# LargeDummyDevice register map
File version: 1.0
Registers are 32-bit, read-write, no defined reset value unless marked. A register's access mark holds for its fields unless they carry their own. Offsets are from the block's base; [hi:lo] are bit positions.

## PERIPHERAL_31
Base 0x4001E000
0x04 REG_1 — Register 1
  [32:31] FIELD_11, [32:30] FIELD_14, [33:29] FIELD_12, [31:28] FIELD_8, [26] FIELD_7, [29:25] FIELD_15, [23:22] FIELD_5, [26:22] FIELD_9, [24:22] FIELD_10, [15] FIELD_3, [15] FIELD_16, [14] FIELD_4, [10:7] FIELD_6, [8:5] FIELD_1, [7:3] FIELD_2, [3:2] FIELD_13
0x08 REG_2 — Register 2
  [33:30] FIELD_8, [30] FIELD_14, [29:25] FIELD_9, [25] FIELD_12, [28:24] FIELD_2, [28:24] FIELD_3, [27:23] FIELD_4, [25:22] FIELD_1, [25:22] FIELD_10, [23:21] FIELD_13, [21:19] FIELD_5, [14:10] FIELD_11, [9:8] FIELD_7, [7] FIELD_16, [11:7] FIELD_17, [3] FIELD_6, [4:0] FIELD_15
0x0C REG_3 — Register 3
  [33:29] FIELD_3, [33:29] FIELD_15, [28] FIELD_11, [29:27] FIELD_18, [23:21] FIELD_9, [24:20] FIELD_4, [20:18] FIELD_7, [19:17] FIELD_8, [20:16] FIELD_1, [14:12] FIELD_2, [11] FIELD_5, [6:5] FIELD_12, [8:5] FIELD_13, [6:4] FIELD_10, [6:3] FIELD_14, [2] FIELD_16, [1:0] FIELD_6, [2:0] FIELD_17
0x10 REG_4 — Register 4
  [31:29] FIELD_19, [30:28] FIELD_12, [27] FIELD_3, [22] FIELD_10, [22] FIELD_11, [21] FIELD_15, [20] FIELD_7, [18] FIELD_13, [18] FIELD_21, [18:15] FIELD_1, [19:15] FIELD_8, [19:15] FIELD_9, [19:15] FIELD_18, [18:15] FIELD_22, [16:13] FIELD_23, [12:11] FIELD_4, [14:10] FIELD_20, [9:7] FIELD_17, [8:6] FIELD_5, [8:6] FIELD_6, [8:5] FIELD_25, [2] FIELD_14, [2] FIELD_16, [5:1] FIELD_2, [2:0] FIELD_24
0x14 REG_5 — Register 5
  [32:30] FIELD_11, [25:24] FIELD_7, [23:20] FIELD_5, [18] FIELD_1, [15] FIELD_2, [19:15] FIELD_8, [17:15] FIELD_10, [14] FIELD_15, [14:13] FIELD_14, [13] FIELD_17, [13:12] FIELD_13, [12:10] FIELD_9, [12:10] FIELD_16, [12:9] FIELD_4, [8:7] FIELD_3, [6:4] FIELD_12, [2:1] FIELD_6
0x18 REG_6 — Register 6
  [34:31] FIELD_13, [33:30] FIELD_16, [31:29] FIELD_8, [31:28] FIELD_21, [25] FIELD_18, [26:24] FIELD_11, [22] FIELD_6, [26:22] FIELD_14, [23:21] FIELD_3, [24:21] FIELD_19, [25:21] FIELD_26, [24:20] FIELD_15, [19] FIELD_24, [16:15] FIELD_12, [14] FIELD_23, [13] FIELD_5, [15:12] FIELD_7, [16:12] FIELD_9, [14:11] FIELD_1, [12:11] FIELD_29, [14:10] FIELD_2, [11:10] FIELD_10, [13:10] FIELD_22, [13:9] FIELD_20, [8] FIELD_17, [10:7] FIELD_27, [9:6] FIELD_28, [5] FIELD_25, [3] FIELD_4
0x1C REG_7 — Register 7
  [17] FIELD_2, [19:16] FIELD_1, [16:15] FIELD_3
0x20 REG_8 — Register 8
  [30:29] FIELD_12, [32:28] FIELD_5, [30:28] FIELD_6, [27:24] FIELD_10, [25:23] FIELD_2, [26:22] FIELD_11, [15] FIELD_9, [15:13] FIELD_4, [12] FIELD_13, [8:6] FIELD_8, [7:3] FIELD_3, [5:1] FIELD_1, [3:0] FIELD_7
0x24 REG_9 — Register 9
  [33:30] FIELD_3, [30] FIELD_15, [29] FIELD_4, [30:27] FIELD_9, [25] FIELD_6, [25:21] FIELD_14, [21:18] FIELD_1, [18] FIELD_11, [22:18] FIELD_19, [18:17] FIELD_2, [20:16] FIELD_18, [15:14] FIELD_10, [16:13] FIELD_12, [17:13] FIELD_17, [13:12] FIELD_7, [10:7] FIELD_13, [9:7] FIELD_21, [9:6] FIELD_5, [3] FIELD_8, [1] FIELD_20, [1:0] FIELD_16
0x28 REG_10 — Register 10
  [33:31] FIELD_15, [32:30] FIELD_9, [33:30] FIELD_18, [26:24] FIELD_14, [26:23] FIELD_7, [25:21] FIELD_3, [22:19] FIELD_11, [15] FIELD_4, [16:14] FIELD_16, [14:11] FIELD_8, [13:11] FIELD_13, [10] FIELD_12, [10] FIELD_17, [11:9] FIELD_19, [7] FIELD_2, [9:7] FIELD_5, [7:4] FIELD_1, [5:2] FIELD_6, [0] FIELD_10
0x2C REG_11 — Register 11
  [34:31] FIELD_2, [34:31] FIELD_8, [31:29] FIELD_1, [31:29] FIELD_10, [28] FIELD_7, [28] FIELD_9, [27:26] FIELD_15, [24] FIELD_17, [21] FIELD_14, [21] FIELD_16, [19:16] FIELD_12, [19:15] FIELD_5, [15:14] FIELD_11, [18:14] FIELD_18, [15:13] FIELD_4, [14:13] FIELD_13, [11:8] FIELD_3, [7:4] FIELD_6
0x30 REG_12 — Register 12
  [31] FIELD_7, [32:31] FIELD_14, [30:28] FIELD_10, [31:28] FIELD_22, [27] FIELD_11, [28:27] FIELD_17, [30:27] FIELD_21, [24] FIELD_3, [22] FIELD_12, [26:22] FIELD_25, [23:21] FIELD_6, [22:18] FIELD_13, [16] FIELD_20, [16] FIELD_26, [15:14] FIELD_4, [15:14] FIELD_9, [17:14] FIELD_15, [16:13] FIELD_23, [15:11] FIELD_5, [15:11] FIELD_24, [14:10] FIELD_19, [9:6] FIELD_18, [8:5] FIELD_16, [7:3] FIELD_1, [4:2] FIELD_2, [5:1] FIELD_8
0x34 REG_13 — Register 13
  [33:31] FIELD_22, [32:30] FIELD_12, [30:28] FIELD_3, [32:28] FIELD_4, [29:27] FIELD_14, [28:27] FIELD_24, [19] FIELD_19, [22:18] FIELD_11, [16:12] FIELD_7, [12] FIELD_18, [13:12] FIELD_21, [15:11] FIELD_16, [11] FIELD_23, [9:8] FIELD_13, [10:8] FIELD_15, [9:7] FIELD_1, [8:7] FIELD_8, [8:7] FIELD_10, [8:7] FIELD_17, [10:6] FIELD_9, [5:4] FIELD_6, [4:1] FIELD_20, [1:0] FIELD_2, [3:0] FIELD_5
0x38 REG_14 — Register 14
  [33:31] FIELD_8, [33:30] FIELD_20, [28] FIELD_6, [29:28] FIELD_27, [29:27] FIELD_12, [31:27] FIELD_17, [27:26] FIELD_3, [25] FIELD_24, [22] FIELD_9, [22] FIELD_18, [21] FIELD_26, [20] FIELD_29, [19:18] FIELD_13, [21:18] FIELD_30, [17:16] FIELD_5, [17:15] FIELD_7, [17:13] FIELD_14, [13] FIELD_19, [10] FIELD_25, [12:9] FIELD_15, [10:8] FIELD_21, [10:8] FIELD_23, [11:7] FIELD_16, [10:6] FIELD_1, [5:4] FIELD_2, [6:4] FIELD_22, [5:2] FIELD_10, [3:2] FIELD_11, [2:0] FIELD_4, [3:0] FIELD_28
0x3C REG_15 — Register 15
  [28:27] FIELD_8, [25] FIELD_4, [25:24] FIELD_2, [21:18] FIELD_5, [20:17] FIELD_7, [17:16] FIELD_12, [15:13] FIELD_6, [4] FIELD_3, [5:2] FIELD_11, [5:1] FIELD_9, [1:0] FIELD_1, [1:0] FIELD_10
0x40 REG_16 — Register 16
  [31] FIELD_7, [28:26] FIELD_5, [27:25] FIELD_8, [27:24] FIELD_10, [23:21] FIELD_3, [20:17] FIELD_9, [13:9] FIELD_4, [9:6] FIELD_11, [7:4] FIELD_2, [2] FIELD_1, [4:2] FIELD_6, [3:0] FIELD_12
0x44 REG_17 — Register 17
  [32:31] FIELD_9, [22] FIELD_5, [15:11] FIELD_4, [9] FIELD_3, [10:7] FIELD_8, [8:6] FIELD_6, [7:5] FIELD_7, [5:2] FIELD_2, [2:0] FIELD_1
0x48 REG_18 — Register 18
  [31] FIELD_1, [27] FIELD_15, [25] FIELD_18, [24] FIELD_9, [26:22] FIELD_6, [21:20] FIELD_5, [21:18] FIELD_14, [15] FIELD_2, [13] FIELD_16, [13:11] FIELD_17, [14:10] FIELD_8, [14:10] FIELD_12, [10:9] FIELD_13, [10:8] FIELD_4, [8:7] FIELD_19, [6:5] FIELD_11, [6:4] FIELD_10, [3] FIELD_7, [2:0] FIELD_3
0x4C REG_19 — Register 19
  [31:29] FIELD_9, [28:26] FIELD_3, [25:22] FIELD_8, [23:21] FIELD_4, [21:19] FIELD_5, [16:13] FIELD_2, [9] FIELD_7, [4:3] FIELD_1, [2:0] FIELD_6
0x50 REG_20 — Register 20
  [31] FIELD_19, [29:28] FIELD_12, [28:27] FIELD_17, [27:25] FIELD_10, [27:25] FIELD_20, [27:23] FIELD_7, [25:21] FIELD_11, [22:20] FIELD_1, [24:20] FIELD_14, [20:19] FIELD_8, [21:18] FIELD_6, [19:17] FIELD_4, [19:17] FIELD_18, [20:16] FIELD_2, [19:15] FIELD_9, [15:13] FIELD_15, [10:9] FIELD_13, [9:6] FIELD_16, [6:4] FIELD_3, [5:4] FIELD_5
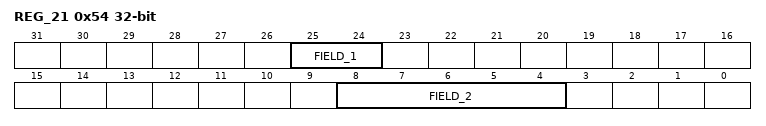
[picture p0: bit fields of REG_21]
0x54 REG_21 — Register 21
  [25:24] FIELD_1, [8:4] FIELD_2
0x58 REG_22 — Register 22
  [32:31] FIELD_20, [31:30] FIELD_6, [30:28] FIELD_16, [27] FIELD_17, [29:25] FIELD_2, [29:25] FIELD_3, [28:25] FIELD_8, [23:22] FIELD_9, [22:19] FIELD_12, [21:18] FIELD_1, [17] FIELD_15, [19:17] FIELD_18, [18:15] FIELD_11, [14] FIELD_13, [15:11] FIELD_7, [13:11] FIELD_10, [7:4] FIELD_5, [5:3] FIELD_4, [3] FIELD_14, [3:0] FIELD_19
0x5C REG_23 — Register 23
  [30:27] FIELD_2, [30:27] FIELD_6, [26:25] FIELD_4, [25:24] FIELD_9, [22:18] FIELD_3, [15] FIELD_1, [17:15] FIELD_5, [13] FIELD_13, [14:10] FIELD_8, [8:7] FIELD_10, [9:7] FIELD_12, [8:5] FIELD_7, [7:3] FIELD_11
0x60 REG_24 — Register 24
  [33:31] FIELD_4, [30] FIELD_10, [34:30] FIELD_14, [32:28] FIELD_9, [31:28] FIELD_23, [31:28] FIELD_25, [28:26] FIELD_1, [26:25] FIELD_3, [26:23] FIELD_12, [27:23] FIELD_26, [25:22] FIELD_24, [24:21] FIELD_7, [21] FIELD_21, [20:19] FIELD_6, [22:19] FIELD_8, [21:19] FIELD_18, [20:16] FIELD_22, [13] FIELD_19, [16:12] FIELD_20, [9] FIELD_11, [10:7] FIELD_2, [6:3] FIELD_15, [6:3] FIELD_16, [4:1] FIELD_5, [4:0] FIELD_13, [0] FIELD_17
0x64 REG_25 — Register 25
  [30] FIELD_16, [28:27] FIELD_25, [30:26] FIELD_8, [30:26] FIELD_13, [26] FIELD_29, [23] FIELD_27, [24:21] FIELD_22, [23:20] FIELD_9, [20] FIELD_23, [19] FIELD_17, [20:18] FIELD_3, [22:18] FIELD_5, [17] FIELD_18, [19:17] FIELD_20, [19:16] FIELD_12, [18:16] FIELD_21, [18:15] FIELD_4, [19:15] FIELD_15, [14:10] FIELD_14, [9] FIELD_10, [10:8] FIELD_2, [9:8] FIELD_19, [8:7] FIELD_11, [8:7] FIELD_28, [5:4] FIELD_7, [4] FIELD_24, [4:3] FIELD_26, [5:2] FIELD_6, [3:1] FIELD_1
0x68 REG_26 — Register 26
  [32:30] FIELD_5, [33:30] FIELD_10, [28] FIELD_9, [30:28] FIELD_16, [29:27] FIELD_1, [21] FIELD_2, [24:20] FIELD_3, [19:18] FIELD_13, [18] FIELD_18, [17] FIELD_4, [17:16] FIELD_14, [18:16] FIELD_17, [15:12] FIELD_8, [6] FIELD_7, [5] FIELD_6, [6:5] FIELD_12, [3:1] FIELD_11, [3:1] FIELD_15
0x6C REG_27 — Register 27
  [34:31] FIELD_20, [35:31] FIELD_31, [26] FIELD_21, [26:25] FIELD_4, [26:25] FIELD_6, [27:25] FIELD_13, [25:24] FIELD_8, [24] FIELD_22, [24:22] FIELD_9, [24:22] FIELD_26, [24:21] FIELD_23, [20:19] FIELD_27, [22:18] FIELD_16, [18:17] FIELD_10, [18:17] FIELD_12, [18:16] FIELD_7, [16:15] FIELD_14, [11] FIELD_25, [12:11] FIELD_29, [12:10] FIELD_1, [14:10] FIELD_15, [9:8] FIELD_2, [11:8] FIELD_5, [11:7] FIELD_30, [9:5] FIELD_28, [4] FIELD_18, [3] FIELD_3, [2] FIELD_19, [5:1] FIELD_11, [4:1] FIELD_17, [2:1] FIELD_24
0x70 REG_28 — Register 28
  [32:29] FIELD_7, [21:19] FIELD_6, [19] FIELD_9, [21:17] FIELD_3, [13:11] FIELD_10, [14:10] FIELD_13, [11:10] FIELD_14, [11:9] FIELD_12, [9:8] FIELD_4, [7:4] FIELD_8, [7:4] FIELD_11, [4:2] FIELD_1, [4:1] FIELD_5, [3:0] FIELD_2
0x74 REG_29 — Register 29
  [32:30] FIELD_4, [30] FIELD_6, [31:30] FIELD_14, [30] FIELD_15, [30:29] FIELD_7, [26:24] FIELD_8, [24:23] FIELD_10, [22] FIELD_17, [18] FIELD_9, [21:17] FIELD_18, [18:15] FIELD_2, [17:15] FIELD_12, [16:15] FIELD_21, [16:14] FIELD_5, [14:13] FIELD_11, [14:12] FIELD_16, [13:10] FIELD_13, [12:8] FIELD_1, [8:6] FIELD_20, [7:4] FIELD_3, [5:1] FIELD_19
0x78 REG_30 — Register 30
  [35:31] FIELD_4, [32:29] FIELD_13, [25] FIELD_1, [21:20] FIELD_10, [19] FIELD_14, [16:15] FIELD_12, [18:14] FIELD_9, [13:10] FIELD_11, [9:7] FIELD_6, [5] FIELD_2, [6:5] FIELD_8, [4:2] FIELD_5, [3:1] FIELD_7, [2:0] FIELD_3
0x7C REG_31 — Register 31
  [31] FIELD_19, [32:29] FIELD_16, [32:28] FIELD_9, [27:24] FIELD_23, [24] FIELD_29, [27:23] FIELD_8, [26:23] FIELD_15, [22] FIELD_1, [22:21] FIELD_3, [22:21] FIELD_25, [20] FIELD_2, [24:20] FIELD_24, [23:19] FIELD_4, [20:19] FIELD_12, [19] FIELD_14, [19] FIELD_20, [20:17] FIELD_6, [18:16] FIELD_13, [16] FIELD_30, [14] FIELD_26, [15:13] FIELD_10, [12:10] FIELD_18, [10:7] FIELD_22, [9:7] FIELD_27, [8:7] FIELD_32, [8:6] FIELD_5, [9:6] FIELD_17, [9:6] FIELD_28, [3] FIELD_7, [4:2] FIELD_11, [5:2] FIELD_31, [2:1] FIELD_21
0x80 REG_32 — Register 32
  [34:31] FIELD_1, [35:31] FIELD_6, [31:30] FIELD_11, [32:29] FIELD_5, [27] FIELD_18, [31:27] FIELD_21, [28:25] FIELD_22, [24] FIELD_2, [25:24] FIELD_12, [26:23] FIELD_28, [22:20] FIELD_4, [20:19] FIELD_23, [22:18] FIELD_9, [20:18] FIELD_13, [19:16] FIELD_19, [18:16] FIELD_25, [15:14] FIELD_24, [15:11] FIELD_15, [10] FIELD_27, [11:8] FIELD_7, [8] FIELD_20, [10:7] FIELD_3, [10:6] FIELD_17, [8:4] FIELD_14, [4] FIELD_26, [5:3] FIELD_29, [2] FIELD_16, [4:0] FIELD_8, [0] FIELD_10
0x84 REG_33 — Register 33
  [31:29] FIELD_2, [30:26] FIELD_8, [23:22] FIELD_4, [25:21] FIELD_11, [20:16] FIELD_1, [16] FIELD_3, [15:11] FIELD_5, [8] FIELD_9, [8] FIELD_10, [8:6] FIELD_7, [2:0] FIELD_6
0x88 REG_34 — Register 34
  [29:28] FIELD_23, [27] FIELD_19, [31:27] FIELD_25, [27:25] FIELD_15, [26:25] FIELD_24, [27:23] FIELD_5, [25:23] FIELD_20, [20:18] FIELD_16, [18:17] FIELD_26, [20:17] FIELD_27, [17:16] FIELD_17, [15:14] FIELD_1, [16:13] FIELD_2, [15:13] FIELD_10, [14:12] FIELD_7, [12:9] FIELD_29, [9:7] FIELD_3, [10:7] FIELD_6, [8:7] FIELD_9, [11:7] FIELD_18, [6] FIELD_12, [7:6] FIELD_22, [5] FIELD_21, [4:3] FIELD_28, [5:2] FIELD_13, [4:1] FIELD_8, [5:1] FIELD_11, [3:0] FIELD_4, [3:0] FIELD_14
0x8C REG_35 — Register 35
  [31:30] FIELD_3, [30:27] FIELD_1, [12:11] FIELD_2, [6] FIELD_4
0x90 REG_36 — Register 36
  [34:30] FIELD_7, [31:29] FIELD_16, [26:25] FIELD_12, [25:24] FIELD_4, [26:24] FIELD_6, [27:24] FIELD_11, [25:22] FIELD_5, [24:21] FIELD_14, [20:18] FIELD_1, [21:18] FIELD_9, [16:14] FIELD_13, [8] FIELD_15, [9:5] FIELD_10, [5:1] FIELD_3, [4:0] FIELD_2, [2:0] FIELD_8
0x94 REG_37 — Register 37
  [32:31] FIELD_18, [32:30] FIELD_4, [33:30] FIELD_13, [33:29] FIELD_2, [33:29] FIELD_10, [30:28] FIELD_8, [28] FIELD_25, [31:27] FIELD_24, [28:25] FIELD_3, [25:23] FIELD_30, [26:22] FIELD_9, [22] FIELD_11, [25:22] FIELD_19, [24:20] FIELD_14, [21:20] FIELD_23, [20:19] FIELD_16, [18:16] FIELD_12, [19:15] FIELD_17, [17:14] FIELD_28, [17:13] FIELD_29, [16:12] FIELD_1, [15:11] FIELD_20, [10:9] FIELD_5, [9:8] FIELD_6, [9:7] FIELD_22, [10:6] FIELD_7, [5] FIELD_15, [7:4] FIELD_26, [6:4] FIELD_27, [5:1] FIELD_21
0x98 REG_38 — Register 38
  [32:31] FIELD_18, [31:29] FIELD_9, [33:29] FIELD_12, [29] FIELD_14, [29:28] FIELD_17, [28:25] FIELD_15, [27:24] FIELD_16, [24:23] FIELD_4, [22:19] FIELD_13, [20:18] FIELD_2, [20:17] FIELD_6, [17] FIELD_7, [15] FIELD_3, [17:14] FIELD_8, [12:10] FIELD_11, [13:9] FIELD_1, [7:5] FIELD_10, [5:2] FIELD_5
0x9C REG_39 — Register 39
  [33:31] FIELD_21, [32:29] FIELD_13, [29:26] FIELD_9, [27:25] FIELD_18, [28:25] FIELD_23, [27:23] FIELD_7, [23:22] FIELD_15, [26:22] FIELD_16, [24:20] FIELD_1, [19:18] FIELD_11, [20:17] FIELD_2, [20:17] FIELD_8, [18:16] FIELD_24, [17:14] FIELD_19, [13:11] FIELD_3, [14:11] FIELD_10, [12:10] FIELD_12, [13:10] FIELD_20, [9] FIELD_22, [7:6] FIELD_14, [8:5] FIELD_4, [4:2] FIELD_5, [2] FIELD_6, [1:0] FIELD_17
0xA0 REG_40 — Register 40
  [32:31] FIELD_13, [33:30] FIELD_10, [29] FIELD_11, [31:29] FIELD_15, [31:28] FIELD_3, [27] FIELD_8, [26] FIELD_17, [28:24] FIELD_19, [22] FIELD_12, [23:22] FIELD_16, [22:21] FIELD_4, [18:17] FIELD_14, [19:16] FIELD_7, [19:15] FIELD_2, [18:15] FIELD_18, [17:14] FIELD_9, [16:12] FIELD_5, [11] FIELD_1, [10:8] FIELD_20, [7:3] FIELD_6
0xA4 REG_41 — Register 41
  [30:29] FIELD_3, [29:28] FIELD_1, [28:26] FIELD_9, [26:25] FIELD_8, [28:25] FIELD_11, [27:24] FIELD_7, [21:18] FIELD_4, [17:16] FIELD_12, [16:14] FIELD_2, [11] FIELD_5, [10] FIELD_10, [11:10] FIELD_13, [6:5] FIELD_6, [6:5] FIELD_15, [5:3] FIELD_14
